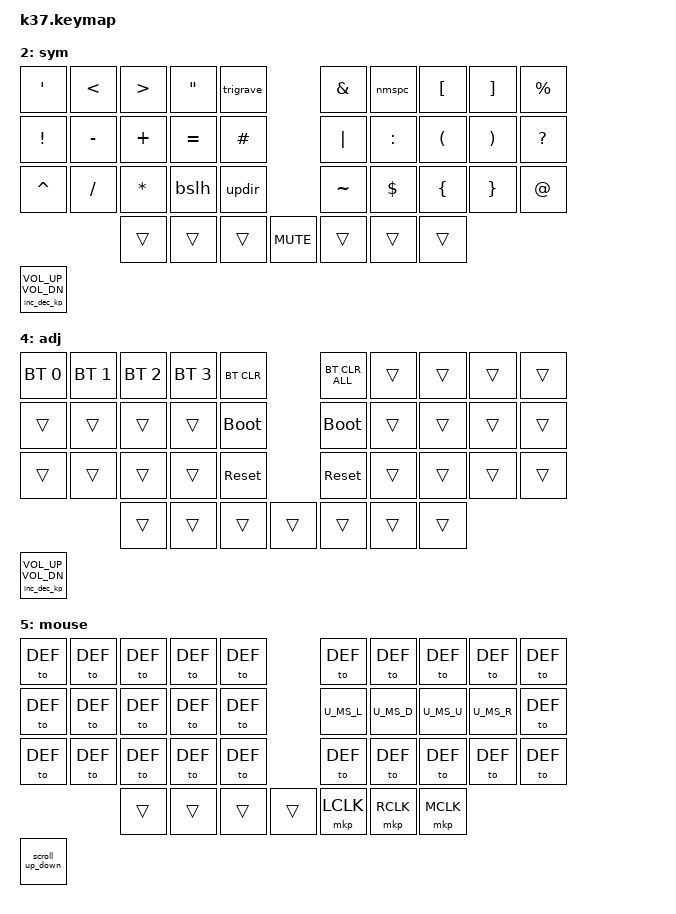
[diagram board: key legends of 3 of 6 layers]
/*
 * Copyright (c) 2020 The ZMK Contributors
 *
 * SPDX-License-Identifier: MIT
 */

#include <behaviors.dtsi>
#include <dt-bindings/zmk/keys.h>
#include <dt-bindings/zmk/bt.h>
#include <dt-bindings/zmk/outputs.h>

#include "keypos_37keys.h"
#include "helper.h"

#define DEF 0
#define NUM 1
#define SYM 2
#define BRWSR 3
#define ADJ 4
#define MOUSE 5

#include "combos.dtsi"
#include "mouse.dtsi"

#define ___ &trans

#define QUICK_TAP_MS 175

/* Homerow mods */
#define KEYS_L LT0 LT1 LT2 LT3 LT4 LM0 LM1 LM2 LM3 LM4 LB0 LB1 LB2 LB3 LB4  // left hand
#define KEYS_R RT0 RT1 RT2 RT3 RT4 RM0 RM1 RM2 RM3 RM4 RB0 RB1 RB2 RB3 RB4  // right hand
#define THUMBS LH2 LH1 LH0 RH0 RH1 RH2                                      // thumbs

#define MAKE_HRM(NAME, HOLD, TAP, TRIGGER_POS) \
    ZMK_BEHAVIOR(NAME, hold_tap, \
        flavor = "balanced"; \
        tapping-term-ms = <280>; \
        quick-tap-ms = <QUICK_TAP_MS>; \
        require-prior-idle-ms = <150>; \
        bindings = <HOLD>, <TAP>; \
        hold-trigger-key-positions = <TRIGGER_POS>; \
        hold-trigger-on-release; \
    )
MAKE_HRM(hml, &kp, &kp, KEYS_R THUMBS)  // left-hand HRMs
MAKE_HRM(hmr, &kp, &kp, KEYS_L THUMBS)  // right-hand HRMs
/* End homerow mods */

/* Hold-tap for base layer */
ZMK_BEHAVIOR(tht, hold_tap,
    flavor = "tap-preferred";
    tapping-term-ms = <200>;
    quick-tap-ms = <400>;
    bindings = <&kp>, <&kp>;
)
/* Hold-tap with caps_word on hold */
ZMK_BEHAVIOR(kp_caps, hold_tap,
    flavor = "tap-preferred";
    tapping-term-ms = <200>;
    quick-tap-ms = <400>;
    bindings = <&caps_word>, <&kp>;
)

&mt {
    quick-tap-ms = <400>;
};

&sk {
    release-after-ms = <2500>;
    quick-release;
};

&lt {
    flavor = "balanced";
    tapping-term-ms = <200>;
    quick-tap-ms = <QUICK_TAP_MS>;
};

ZMK_CONDITIONAL_LAYER(NUM SYM, ADJ)  // NUM + SYM --> ADJ

MACRO(updir, &kp DOT &kp DOT &kp FSLH)
MACRO(nmspc, &kp COLON &kp COLON)
MACRO(bslh, &kp BSLH &kp BSLH)
MACRO(trigrave, &kp GRAVE &kp GRAVE &kp GRAVE)
SIMPLE_MORPH(bspc_del, SFT, &kp BSPC, &kp DEL)

#define NAV_LEFT  &mt LC(LEFT) LEFT
#define NAV_RIGHT &mt LC(RIGHT) RIGHT
#define CS(arg) LC(LS(arg))
#define layout LG(SPACE)

ZMK_LAYER(default,
     // ╭─────────────┬─────────────┬─────────────┬─────────────┬─────────────╮             ╭─────────────┬─────────────┬─────────────┬─────────────┬─────────────╮
          &kp Q         &tht LC(W) W  &kp E         &kp R         &tht GRAVE T                &kp Y         &kp U         &kp I         &kp O         &tht LBKT P
     // ├─────────────┼─────────────┼─────────────┼─────────────┼─────────────┤             ├─────────────┼─────────────┼─────────────┼─────────────┼─────────────┤
          &hml LGUI A   &hml LALT S   &hml LCTRL D  &hml LSHFT F  &kp G                       &kp H         &hmr RSHFT J  &hmr RCTRL K  &hmr RALT L  &tht SQT SEMI
     // ├─────────────┼─────────────┼─────────────┼─────────────┼─────────────┤             ├─────────────┼─────────────┼─────────────┼─────────────┼─────────────┤
          &kp Z         &kp X        &tht CS(C) C  &tht CS(V) V   &kp B                       &kp N         &tht RBKT M   &kp COMMA     &kp DOT       &kp FSLH
     // ╰─────────────┼─────────────┼─────────────┼─────────────┼─────────────┼─────────────┼─────────────┼─────────────┼─────────────┼─────────────┼─────────────╯
                                   &lt BRWSR layout &lt SYM TAB   &kp SPACE    &kp LG(LS(S))  &bspc_del     &mo NUM       &kp_caps 0 BSLH
     //                             ╰─────────────┴─────────────┴─────────────┴─────────────┴─────────────┴─────────────┴─────────────╯
     , &inc_dec_kp LC(RG(RIGHT)) LC(RG(LEFT))
 )

ZMK_LAYER(num,
     // ╭─────────────┬─────────────┬─────────────┬─────────────┬─────────────╮             ╭─────────────┬─────────────┬─────────────┬─────────────┬─────────────╮
          &kp N1        &kp N2        &kp N3        &kp N4        &kp N5                       &kp N6        &kp N7       &kp N8        &kp N9        &kp N0
     // ├─────────────┼─────────────┼─────────────┼─────────────┼─────────────┤             ├─────────────┼─────────────┼─────────────┼─────────────┼─────────────┤
          &sk LGUI      &sk LALT      &sk LCTRL     &sk LSHFT     &none                        NAV_LEFT      &kp DOWN      &kp UP        NAV_RIGHT     &none
     // ├─────────────┼─────────────┼─────────────┼─────────────┼─────────────┤             ├─────────────┼─────────────┼─────────────┼─────────────┼─────────────┤
          &kp F1        &kp F2        &kp F3        &kp F4        &kp F5                        &kp F6       &kp F7       &kp F8         &kp F9        &kp F10
     // ╰─────────────┼─────────────┼─────────────┼─────────────┼─────────────┼─────────────┼─────────────┼─────────────┼─────────────┼─────────────┼─────────────╯
                                      &kp F11         ___           ___             ___        ___           ___         &kp F12
     //                             ╰─────────────┴─────────────┴─────────────┴─────────────┴─────────────┴─────────────┴─────────────╯
     , &inc_dec_kp LC(TAB) CS(TAB)
)

ZMK_LAYER(sym,
     // ╭─────────────┬─────────────┬─────────────┬─────────────┬─────────────╮             ╭─────────────┬─────────────┬─────────────┬─────────────┬─────────────╮
          &kp APOS         &kp LT       &kp GT       &kp DQT      &trigrave                    &kp AMPS     &nmspc        &kp LBKT       &kp RBKT     &kp PRCNT
     // ├─────────────┼─────────────┼─────────────┼─────────────┼─────────────┤             ├─────────────┼─────────────┼─────────────┼─────────────┼─────────────┤
          &kp EXCL         &kp MINUS    &kp PLUS     &kp EQUAL    &kp HASH                     &kp PIPE     &kp COLON     &kp LPAR       &kp RPAR     &kp QMARK
     // ├─────────────┼─────────────┼─────────────┼─────────────┼─────────────┤             ├─────────────┼─────────────┼─────────────┼─────────────┼─────────────┤
          &kp CARET        &kp FSLH     &kp STAR     &bslh        &updir                       &kp TILDE    &kp DLLR      &kp LBRC       &kp RBRC     &kp AT
     // ╰─────────────┼─────────────┼─────────────┼─────────────┼─────────────┼─────────────┼─────────────┼─────────────┼─────────────┼─────────────┼─────────────╯
                                      ___           ___           ___           &kp C_MUTE       ___           ___           ___
     //                             ╰─────────────┴─────────────┴─────────────┴─────────────┴─────────────┴─────────────┴─────────────╯
     , &inc_dec_kp C_VOL_UP C_VOL_DN
)

ZMK_LAYER(browser,
     // ╭─────────────┬─────────────┬─────────────┬─────────────┬─────────────╮             ╭─────────────┬─────────────┬─────────────┬─────────────┬─────────────╮
          ___           &kp LC(W)     &kp CS(T)     &kp LC(R)     &kp LC(T)                    ___           ___           ___           ___           ___
     // ├─────────────┼─────────────┼─────────────┼─────────────┼─────────────┤             ├─────────────┼─────────────┼─────────────┼─────────────┼─────────────┤
          ___           ___           &kp LA(LEFT)  &kp LA(RIGHT) ___                          ___           ___           ___           ___           ___
     // ├─────────────┼─────────────┼─────────────┼─────────────┼─────────────┤             ├─────────────┼─────────────┼─────────────┼─────────────┼─────────────┤
          ___           ___           &kp CS(TAB)   &kp LC(TAB)   ___                          ___           ___           ___           ___           ___
     // ╰─────────────┼─────────────┼─────────────┼─────────────┼─────────────┼─────────────┼─────────────┼─────────────┼─────────────┼─────────────┼─────────────╯
                                      ___           ___           ___               ___        ___           ___           ___
     //                             ╰─────────────┴─────────────┴─────────────┴─────────────┴─────────────┴─────────────┴─────────────╯
     , &inc_dec_kp LC(TAB) CS(TAB)
)

ZMK_LAYER(adj,
     // ╭─────────────┬─────────────┬─────────────┬─────────────┬─────────────╮             ╭─────────────┬─────────────┬─────────────┬─────────────┬─────────────╮
          &bt BT_SEL 0 &bt BT_SEL 1   &bt BT_SEL 2 &bt BT_SEL 3   &bt BT_CLR                 &bt BT_CLR_ALL  ___          ___           ___           ___
     // ├─────────────┼─────────────┼─────────────┼─────────────┼─────────────┤             ├─────────────┼─────────────┼─────────────┼─────────────┼─────────────┤
          ___           ___           ___           ___           &bootloader                 &bootloader   ___           ___           ___           ___
     // ├─────────────┼─────────────┼─────────────┼─────────────┼─────────────┤             ├─────────────┼─────────────┼─────────────┼─────────────┼─────────────┤
          ___           ___           ___           ___           &sys_reset                  &sys_reset    ___           ___           ___           ___
     // ╰─────────────┼─────────────┼─────────────┼─────────────┼─────────────┼─────────────┼─────────────┼─────────────┼─────────────┼─────────────┼─────────────╯
                                      ___           ___           ___               ___       ___           ___           ___
     //                             ╰─────────────┴─────────────┴─────────────┴─────────────┴─────────────┴─────────────┴─────────────╯
     , &inc_dec_kp C_VOL_UP C_VOL_DN
)

ZMK_LAYER(mouse,
     // ╭─────────────┬─────────────┬─────────────┬─────────────┬─────────────╮             ╭─────────────┬─────────────┬─────────────┬─────────────┬─────────────╮
          &to DEF       &to DEF       &to DEF       &to DEF       &to DEF                      &to DEF       &to DEF       &to DEF       &to DEF       &to DEF
     // ├─────────────┼─────────────┼─────────────┼─────────────┼─────────────┤             ├─────────────┼─────────────┼─────────────┼─────────────┼─────────────┤
          &to DEF       &to DEF       &to DEF       &to DEF       &to DEF                      U_MS_L        U_MS_D        U_MS_U        U_MS_R        &to DEF
     // ├─────────────┼─────────────┼─────────────┼─────────────┼─────────────┤             ├─────────────┼─────────────┼─────────────┼─────────────┼─────────────┤
          &to DEF       &to DEF       &to DEF       &to DEF       &to DEF                      &to DEF       &to DEF       &to DEF       &to DEF       &to DEF
     // ╰─────────────┼─────────────┼─────────────┼─────────────┼─────────────┼─────────────┼─────────────┼─────────────┼─────────────┼─────────────┼─────────────╯
                                      ___           ___           ___               ___       &mkp LCLK     &mkp RCLK     &mkp MCLK
     //                             ╰─────────────┴─────────────┴─────────────┴─────────────┴─────────────┴─────────────┴─────────────╯
     , &scroll_up_down
)
